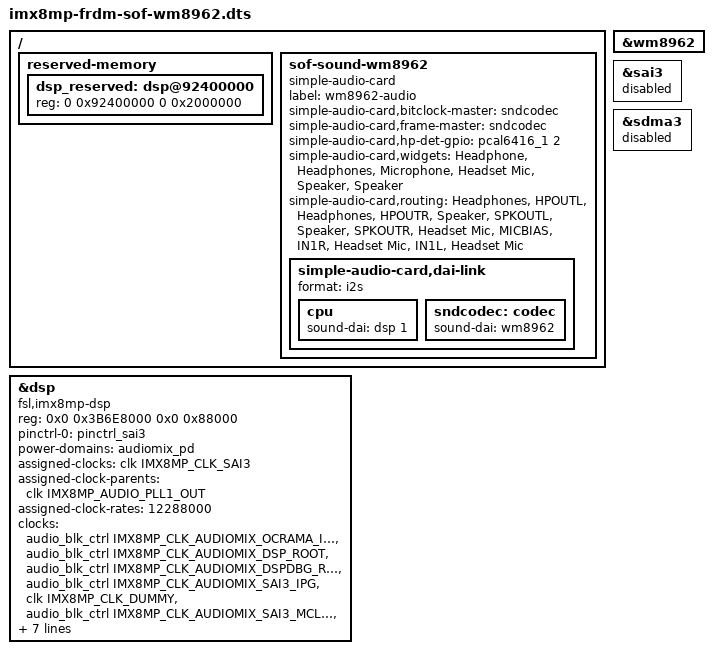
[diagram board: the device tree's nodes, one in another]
// SPDX-License-Identifier: GPL-2.0+
/*
 * Copyright 2026
 *
 * FRDM-IMX8MP Sound Open Firmware (SOF) + on-board WM8962 codec.
 * Ported from imx8mp-evk-revb4-sof-wm8962.dts (i.MX Linux 6.6.52_2.2.0).
 *
 * Differences vs the EVK revb4 template:
 *  - base board dts is imx8mp-frdm.dts, which already defines the wm8962
 *    codec node (I2C addr 0x1a, MCLK from SAI3) - only #sound-dai-cells added
 *  - headphone detect is wired to IO expander pcal6416_1 pin 2 (EVK: gpio4 28)
 *  - the base board does not reserve DSP memory, so dsp_reserved is ADDED here
 *    (the EVK template instead /delete-node/s its dsp_reserved_heap/dsp_vdev*)
 *  - no digital mic on board, DMIC routing from the template is dropped
 */

#include "imx8mp-frdm.dts"

/ {
	/* remove the legacy (non-SOF) wm8962 sound card, SOF takes over SAI3 */
	/delete-node/ sound-wm8962;

	reserved-memory {
		/* 32MB for SOF firmware/heap, same placement as i.MX8MP EVK */
		dsp_reserved: dsp@92400000 {
			reg = <0 0x92400000 0 0x2000000>;
		};
	};

	sof-sound-wm8962 {
		compatible = "simple-audio-card";
		label = "wm8962-audio";
		simple-audio-card,bitclock-master = <&sndcodec>;
		simple-audio-card,frame-master = <&sndcodec>;
		simple-audio-card,hp-det-gpio = <&pcal6416_1 2 GPIO_ACTIVE_HIGH>;
		simple-audio-card,widgets =
			"Headphone", "Headphones",
			"Microphone", "Headset Mic",
			"Speaker", "Speaker";
		simple-audio-card,routing =
			"Headphones", "HPOUTL",
			"Headphones", "HPOUTR",
			"Speaker", "SPKOUTL",
			"Speaker", "SPKOUTR",
			"Headset Mic", "MICBIAS",
			"IN1R", "Headset Mic",
			"IN1L", "Headset Mic";
		simple-audio-card,dai-link {
			format = "i2s";
			cpu {
				sound-dai = <&dsp 1>;
			};
			sndcodec: codec {
				sound-dai = <&wm8962>;
			};
		};
	};
};

&wm8962 {
	#sound-dai-cells = <0>;
	status = "okay";
};

&dsp {
	#sound-dai-cells = <1>;
	compatible = "fsl,imx8mp-dsp";
	reg = <0x0 0x3B6E8000 0x0 0x88000>;

	pinctrl-names = "default";
	pinctrl-0 = <&pinctrl_sai3>;

	power-domains = <&audiomix_pd>;

	assigned-clocks = <&clk IMX8MP_CLK_SAI3>;
	assigned-clock-parents = <&clk IMX8MP_AUDIO_PLL1_OUT>;
	assigned-clock-rates = <12288000>;
	clocks = <&audio_blk_ctrl IMX8MP_CLK_AUDIOMIX_OCRAMA_IPG>,
		<&audio_blk_ctrl IMX8MP_CLK_AUDIOMIX_DSP_ROOT>,
		<&audio_blk_ctrl IMX8MP_CLK_AUDIOMIX_DSPDBG_ROOT>,
		<&audio_blk_ctrl IMX8MP_CLK_AUDIOMIX_SAI3_IPG>, <&clk IMX8MP_CLK_DUMMY>,
		<&audio_blk_ctrl IMX8MP_CLK_AUDIOMIX_SAI3_MCLK1>, <&clk IMX8MP_CLK_DUMMY>,
		<&clk IMX8MP_CLK_DUMMY>,
		<&audio_blk_ctrl IMX8MP_CLK_AUDIOMIX_SDMA3_ROOT>;
	clock-names = "ipg", "ocram", "core",
		"sai3_bus", "sai3_mclk0", "sai3_mclk1", "sai3_mclk2", "sai3_mclk3",
		"sdma3_root";

	mbox-names = "txdb0", "txdb1", "rxdb0", "rxdb1";
	mboxes = <&mu2 2 0>, <&mu2 2 1>,
		 <&mu2 3 0>, <&mu2 3 1>;
	memory-region = <&dsp_reserved>;
	/delete-property/ firmware-name;

	tplg-name = "sof-imx8mp-wm8962.tplg";
	machine-drv-name = "asoc-simple-card";
	status = "okay";
};

/* SAI3 / SDMA3 are now driven by the SOF firmware through the DSP node */
&sai3 {
	status = "disabled";
};

&sdma3 {
	status = "disabled";
};
